# PIC16LF1907 register map
Vendor: Microchip
Registers are 8-bit, read-write, no defined reset value unless marked. A register's access mark holds for its fields unless they carry their own. Addresses are absolute, and some are shared; only a register's first bit layout is shown; [hi:lo] are bit positions; {n}, {i} and the like mark numbered series.

## SFR
0x00 INDF0 — (power-on value xxxxxxxx)
0x01 INDF1 — (power-on value xxxxxxxx)
0x02 PCL reset 0x0
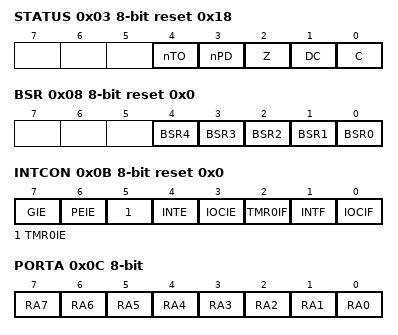
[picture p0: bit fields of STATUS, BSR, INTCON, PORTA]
0x03 STATUS reset 0x18
  [4] nTO ro, [3] nPD ro, [2] Z, [1] DC, [0] C
0x04 FSR0L reset 0x0
0x05 FSR0H reset 0x0
0x06 FSR1L reset 0x0
0x07 FSR1H reset 0x0
0x08 BSR reset 0x0
  [n] BSR{n} (n=0..4)
0x09 WREG reset 0x0
  [7:0] WREG0
0x0A PCLATH reset 0x0
  [6:0] PCLATH
0x0B INTCON reset 0x0
  [7] GIE, [6] PEIE, [5] TMR0IE, [4] INTE, [3] IOCIE, [2] TMR0IF, [1] INTF, [0] IOCIF ro
0x0C PORTA — (power-on value xxxxxxxx)
  [n] RA{n} (n=0..7)
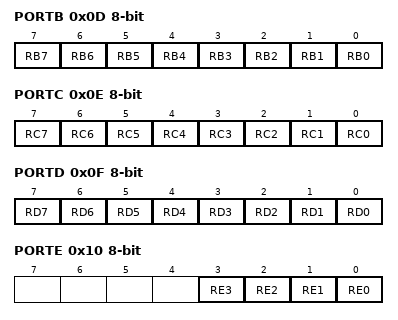
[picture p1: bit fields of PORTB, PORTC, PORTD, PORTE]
0x0D PORTB — (power-on value xxxxxxxx)
  [n] RB{n} (n=0..7)
0x0E PORTC — (power-on value xxxxxxxx)
  [n] RC{n} (n=0..7)
0x0F PORTD — (power-on value xxxxxxxx)
  [n] RD{n} (n=0..7)
0x10 PORTE — (power-on value ----xxxx)
  [3] RE3 ro, [2] RE2, [1] RE1, [0] RE0
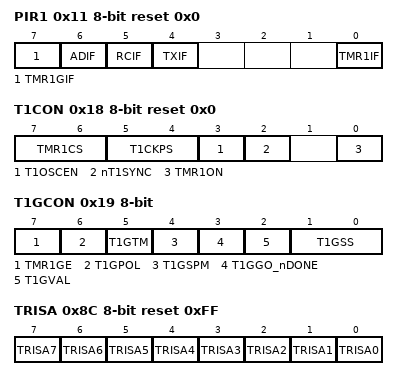
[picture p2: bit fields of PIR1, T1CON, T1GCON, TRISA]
0x11 PIR1 reset 0x0
  [7] TMR1GIF — Timer1 Gate Interrupt Flag bit
  [6] ADIF — A/D Converter Interrupt Flag bit
  [5] RCIF
  [4] TXIF
  [0] TMR1IF — TMR1 Overflow Interrupt Flag bit
0x12 PIR2 reset 0x0
  [2] LCDIF
0x15 TMR0 — (power-on value xxxxxxxx)
0x16 TMR1L — (power-on value xxxxxxxx)
0x17 TMR1H — (power-on value xxxxxxxx)
0x18 T1CON reset 0x0
  [7:6] TMR1CS, [5:4] T1CKPS, [3] T1OSCEN, [2] nT1SYNC, [0] TMR1ON
0x19 T1GCON — (power-on value 00000x00)
  [7] TMR1GE, [6] T1GPOL, [5] T1GTM, [4] T1GSPM, [3] T1GGO_nDONE, [2] T1GVAL ro, [1:0] T1GSS
0x8C TRISA reset 0xFF — PORTA Data Direction Control Register
  [n] TRISA{n} (n=0..7)
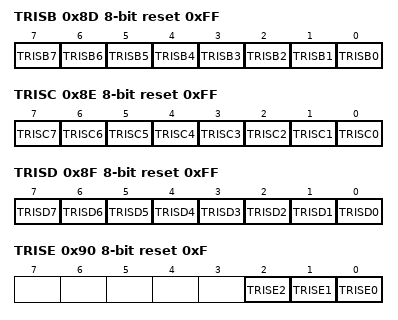
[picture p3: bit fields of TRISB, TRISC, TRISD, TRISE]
0x8D TRISB reset 0xFF — PORTB Data Direction Control Register
  [n] TRISB{n} (n=0..7)
0x8E TRISC reset 0xFF — PORTC Data Direction Control Register
  [n] TRISC{n} (n=0..7)
0x8F TRISD reset 0xFF
  [n] TRISD{n} (n=0..7)
0x90 TRISE reset 0xF
  [2] TRISE2, [1] TRISE1, [0] TRISE0
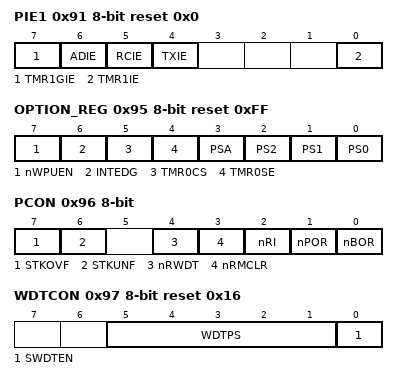
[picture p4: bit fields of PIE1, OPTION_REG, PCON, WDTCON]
0x91 PIE1 reset 0x0 — Peripheral Interrupt Enable Register 1
  [7] TMR1GIE — Timer1 Gate Interrupt Enable bit
  [6] ADIE — A/D Converter Interrupt Enable bit
  [5] RCIE
  [4] TXIE
  [0] TMR1IE — TMR1 Overflow Interrupt Enable bit
0x92 PIE2 reset 0x0 — Peripheral Interrupt Enable Register 2
  [2] LCDIE — LCD Module Interrupt Enable bit
0x95 OPTION_REG reset 0xFF — Option Register
  [7] nWPUEN — Weak Pull-up Enable bit
  [6] INTEDG — Interrupt Edge Select bit
  [5] TMR0CS — TMR0 Clock Source Select bit
  [4] TMR0SE — TMR0 Source Edge Select bit
  [3] PSA — Prescaler Active bit
  [2] PS2 — Prescaler Rate Select bits
  [1] PS1 — Prescaler Rate Select bits
  [0] PS0 — Prescaler Rate Select bits
0x96 PCON — Power Control Register (power-on value 00-111qq)
  [7] STKOVF — Stack Overflow Flag bit
  [6] STKUNF — Stack Underflow Flag bit
  [4] nRWDT
  [3] nRMCLR — MCLR Reset Flag bit
  [2] nRI — RESET Instruction Flag bit
  [1] nPOR — Power-on Reset Status bit
  [0] nBOR — Brown-out Reset Status bit
0x97 WDTCON reset 0x16 — Watchdog Timer Control Register
  [5:1] WDTPS — Watchdog Timer Period Select bits
  [0] SWDTEN — Software Enable/Disable for Watch Dog Timer bit
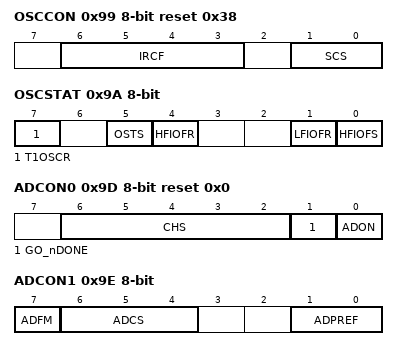
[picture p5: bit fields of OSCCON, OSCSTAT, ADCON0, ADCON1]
0x99 OSCCON reset 0x38 — Oscillator Control Register
  [6:3] IRCF — Internal Oscillator Frequency Select bits
  [1:0] SCS — System clock select bit
0x9A OSCSTAT ro — Oscillator Status Register (power-on value 0-q0--00)
  [7] T1OSCR — Timer1 Oscillator Ready bit
  [5] OSTS — Oscillator Start-up Time-out Status bit
  [4] HFIOFR — High Freqency Internal Oscillator Ready bit
  [1] LFIOFR — Low Freqency Internal Oscillator Ready bit
  [0] HFIOFS — Low Freqency Internal Oscillator Ready bit
0x9B ADRESL — A/D Result Register LSB (power-on value xxxxxxxx)
0x9C ADRESH — A/D Result Register MSB (power-on value xxxxxxxx)
0x9D ADCON0 reset 0x0 — Analog-to-Digital Control Register 0
  [6:2] CHS — Analog Channel Select bits
  [1] GO_nDONE — A/D Conversion Status bit
  [0] ADON — A/D Module Enable bit
0x9E ADCON1 — Analog-to-Digital Control Register 1 (power-on value 0000--xx)
  [7] ADFM — A/D Result Format Select bit
  [6:4] ADCS — A/D Conversion Clock Select bits
  [1:0] ADPREF — A/D positive voltage reference configuration bit
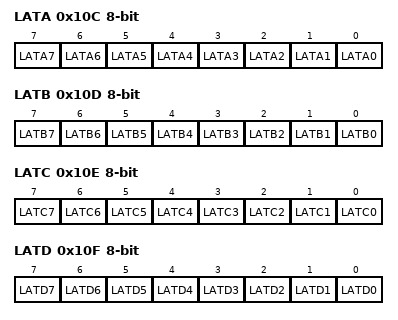
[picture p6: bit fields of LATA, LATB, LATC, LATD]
0x10C LATA — (power-on value xxxxxxxx)
  [n] LATA{n} (n=0..7)
0x10D LATB — (power-on value xxxxxxxx)
  [n] LATB{n} (n=0..7)
0x10E LATC — (power-on value xxxxxxxx)
  [n] LATC{n} (n=0..7)
0x10F LATD — (power-on value xxxxxxxx)
  [n] LATD{n} (n=0..7)
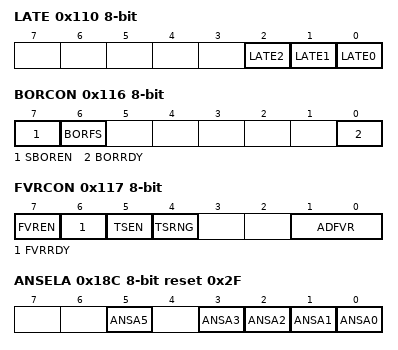
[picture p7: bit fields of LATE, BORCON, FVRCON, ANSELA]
0x110 LATE — (power-on value -----xxx)
  [2] LATE2, [1] LATE1, [0] LATE0
0x116 BORCON — Brown-out Reset Control Register (power-on value 1x-----q)
  [7] SBOREN — Software Brown Out Reset Enable bit
  [6] BORFS — Brown out reset fast start bit
  [0] BORRDY ro — Brown-out Reset Circuit Ready Status bit
0x117 FVRCON — Voltage Reference Control Register 0 (power-on value 0q00--00)
  [7] FVREN — Fixed Voltage Reference Enable
  [6] FVRRDY ro — Fixed Voltage Reference Ready Flag
  [5] TSEN — Temperature Sensor Enable
  [4] TSRNG — Temperature Sensor Range Select
  [1:0] ADFVR — A/D Converter Fixed Voltage Reference Selection
0x18C ANSELA reset 0x2F
  [5] ANSA5, [n] ANSA{n} (n=0..3)
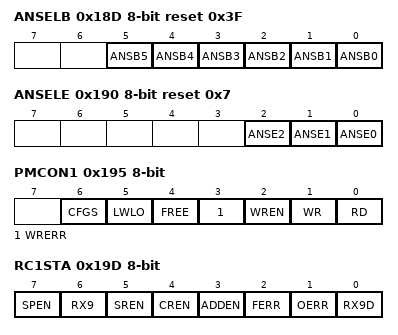
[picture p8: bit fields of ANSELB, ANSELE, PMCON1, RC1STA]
0x18D ANSELB reset 0x3F
  [n] ANSB{n} (n=0..5)
0x190 ANSELE reset 0x7
  [2] ANSE2, [1] ANSE1, [0] ANSE0
0x191 PMADRL reset 0x0
0x192 PMADRH reset 0x80
  [6:0] PMADRH
0x193 PMDATL — (power-on value xxxxxxxx)
0x194 PMDATH — (power-on value --xxxxxx)
  [5:0] PMDATH
0x195 PMCON1 — (power-on value 1000x000)
  [6] CFGS — FLASH Program / Configuration Select bit
  [5] LWLO — Load Write Latches Only bit
  [4] FREE — Program FLASH Erase Enable bit
  [3] WRERR — Sequence Error Flag bit
  [2] WREN — Program/Erase Enable bit
  [1] WR — Write Control bit (can only be set)
  [0] RD — Read Control bit (can only be set)
0x196 PMCON2 wo reset 0x0
0x199 RC1REG reset 0x0
0x19A TX1REG reset 0x0
0x19B SP1BRGL reset 0x0
  [7:0] SPGRGL
0x19C SP1BRGH reset 0x0
  [7:0] SPBRGH
0x19D RC1STA — (power-on value 0000000x)
  [7] SPEN, [6] RX9, [5] SREN, [4] CREN, [3] ADDEN, [2] FERR ro, [1] OERR ro, [0] RX9D ro
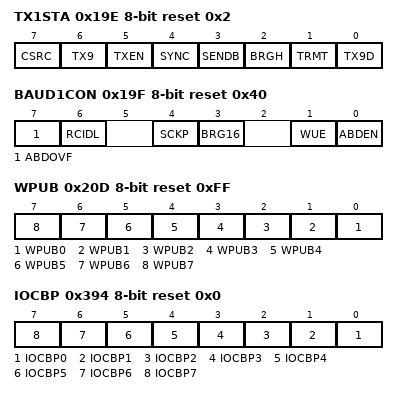
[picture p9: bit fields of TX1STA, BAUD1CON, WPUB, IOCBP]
0x19E TX1STA reset 0x2
  [7] CSRC, [6] TX9, [5] TXEN, [4] SYNC, [3] SENDB, [2] BRGH, [1] TRMT ro, [0] TX9D
0x19F BAUD1CON reset 0x40
  [7] ABDOVF ro, [6] RCIDL ro, [4] SCKP, [3] BRG16, [1] WUE, [0] ABDEN
0x20D WPUB reset 0xFF
  [n] WPUB{n} (n=0..7)
0x210 WPUE reset 0x8
  [3] WPUE3
0x394 IOCBP reset 0x0 — Interrupt-On-Change Positive Edge Register
  [n] IOCBP{n} (n=0..7)
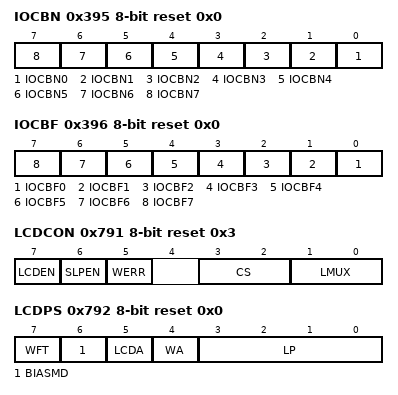
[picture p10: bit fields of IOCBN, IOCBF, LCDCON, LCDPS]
0x395 IOCBN reset 0x0 — Interrupt-On-Change Negative Edge Register
  [n] IOCBN{n} (n=0..7)
0x396 IOCBF reset 0x0 — Interrupt-On-Change Flag Register
  [n] IOCBF{n} (n=0..7)
0x791 LCDCON reset 0x3 — LCD Control Register
  [7] LCDEN — LCD Module Enable bit
  [6] SLPEN — LCD Display Sleep-Enabled bit
  [5] WERR — Write Failed Error bit (can only be cleared)
  [3:2] CS — Clock Source bits
  [1:0] LMUX — Commons Selection bits
0x792 LCDPS reset 0x0 — LCD Phase Register
  [7] WFT — Waveform Type bit
  [6] BIASMD — Bias Mode Selection bit
  [5] LCDA ro — LCD Active bit
  [4] WA ro — Write Allow bit
  [3:0] LP — LCD Prescaler Selection bits
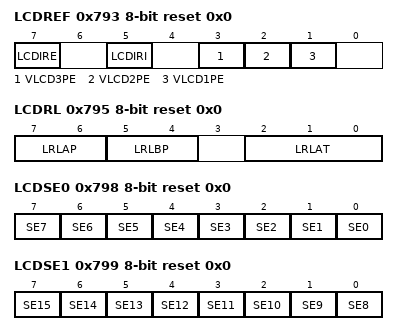
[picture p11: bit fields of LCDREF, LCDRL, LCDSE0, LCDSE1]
0x793 LCDREF reset 0x0 — LCD Reference Voltage Control Register
  [7] LCDIRE — LCD Internal Reference Enable bit
  [5] LCDIRI — LCD Internal Reference Ladder Idle Enable bit
  [3] VLCD3PE — VLCD3 pin enable bit
  [2] VLCD2PE — VLCD2 pin enable bit
  [1] VLCD1PE — VLCD1 pin enable bit
0x794 LCDCST reset 0x0 — LCD Contrast Control Register
  [2:0] LCDCST — LCD Contrast Control bits
0x795 LCDRL reset 0x0 — LCD Reference Voltage Control Register
  [7:6] LRLAP — LCD Reference Ladder A Time Power Control bits
  [5:4] LRLBP — LCD Reference Ladder B Time Power Control bits
  [2:0] LRLAT — LCD Reference Ladder A Time interval control bits
0x798 LCDSE0 reset 0x0
  [n] SE{n} (n=0..7)
0x799 LCDSE1 reset 0x0
  [n-8] SE{n} (n=8..15)
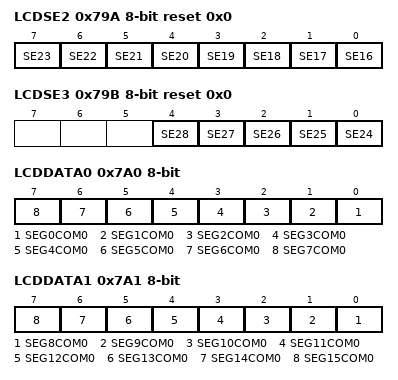
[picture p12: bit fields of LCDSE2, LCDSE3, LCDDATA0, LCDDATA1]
0x79A LCDSE2 reset 0x0
  [n-16] SE{n} (n=16..23)
0x79B LCDSE3 reset 0x0
  [n-24] SE{n} (n=24..28)
0x7A0 LCDDATA0 — (power-on value xxxxxxxx)
  [n] SEG{n}COM0 (n=0..7)
0x7A1 LCDDATA1 — (power-on value xxxxxxxx)
  [n-8] SEG{n}COM0 (n=8..15)
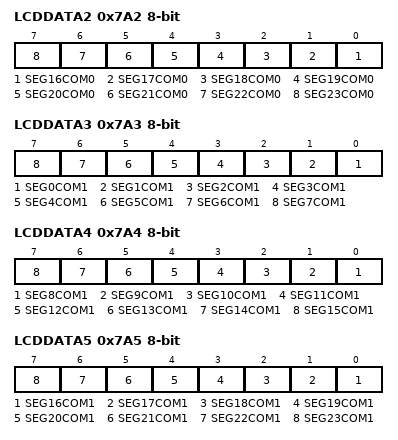
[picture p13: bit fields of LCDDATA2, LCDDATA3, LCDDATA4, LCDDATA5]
0x7A2 LCDDATA2 — (power-on value xxxxxxxx)
  [n-16] SEG{n}COM0 (n=16..23)
0x7A3 LCDDATA3 — (power-on value xxxxxxxx)
  [n] SEG{n}COM1 (n=0..7)
0x7A4 LCDDATA4 — (power-on value xxxxxxxx)
  [n-8] SEG{n}COM1 (n=8..15)
0x7A5 LCDDATA5 — (power-on value xxxxxxxx)
  [n-16] SEG{n}COM1 (n=16..23)
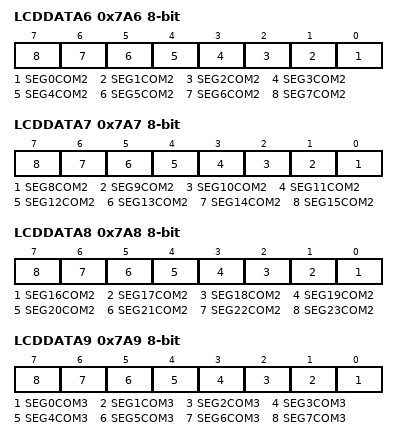
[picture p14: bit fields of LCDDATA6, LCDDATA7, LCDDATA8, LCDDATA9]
0x7A6 LCDDATA6 — (power-on value xxxxxxxx)
  [n] SEG{n}COM2 (n=0..7)
0x7A7 LCDDATA7 — (power-on value xxxxxxxx)
  [n-8] SEG{n}COM2 (n=8..15)
0x7A8 LCDDATA8 — (power-on value xxxxxxxx)
  [n-16] SEG{n}COM2 (n=16..23)
0x7A9 LCDDATA9 — (power-on value xxxxxxxx)
  [n] SEG{n}COM3 (n=0..7)
0x7AA LCDDATA10 — (power-on value xxxxxxxx)
  [n-8] SEG{n}COM3 (n=8..15)
0x7AB LCDDATA11 — (power-on value xxxxxxxx)
  [n-16] SEG{n}COM3 (n=16..23)
0x7AC LCDDATA12 — (power-on value ---xxxxx)
  [n-24] SEG{n}COM0 (n=24..28)
0x7AF LCDDATA15 — (power-on value ---xxxxx)
  [n-24] SEG{n}COM1 (n=24..28)
0x7B2 LCDDATA18 — (power-on value ---xxxxx)
  [n-24] SEG{n}COM2 (n=24..28)
0x7B5 LCDDATA21 — (power-on value ---xxxxx)
  [n-24] SEG{n}COM3 (n=24..28)
0xFE4 STATUS_SHAD — (power-on value -----xxx)
  [2] Z_SHAD, [1] DC_SHAD, [0] C_SHAD
0xFE5 WREG_SHAD — (power-on value xxxxxxxx)
0xFE6 BSR_SHAD — (power-on value ---xxxxx)
  [4:0] BSR_SHAD
0xFE7 PCLATH_SHAD — (power-on value -xxxxxxx)
  [6:0] PCLATH_SHAD
0xFE8 FSR0L_SHAD — (power-on value xxxxxxxx)
0xFE9 FSR0H_SHAD — (power-on value xxxxxxxx)
0xFEA FSR1L_SHAD — (power-on value xxxxxxxx)
0xFEB FSR1H_SHAD — (power-on value xxxxxxxx)
0xFED STKPTR reset 0x1F — Current Stack pointer
  [4:0] STKPTR
0xFEE TOSL — Top of Stack Low byte (power-on value xxxxxxxx)
0xFEF TOSH — Top of Stack High byte (power-on value -xxxxxxx)
  [6:0] TOSH
